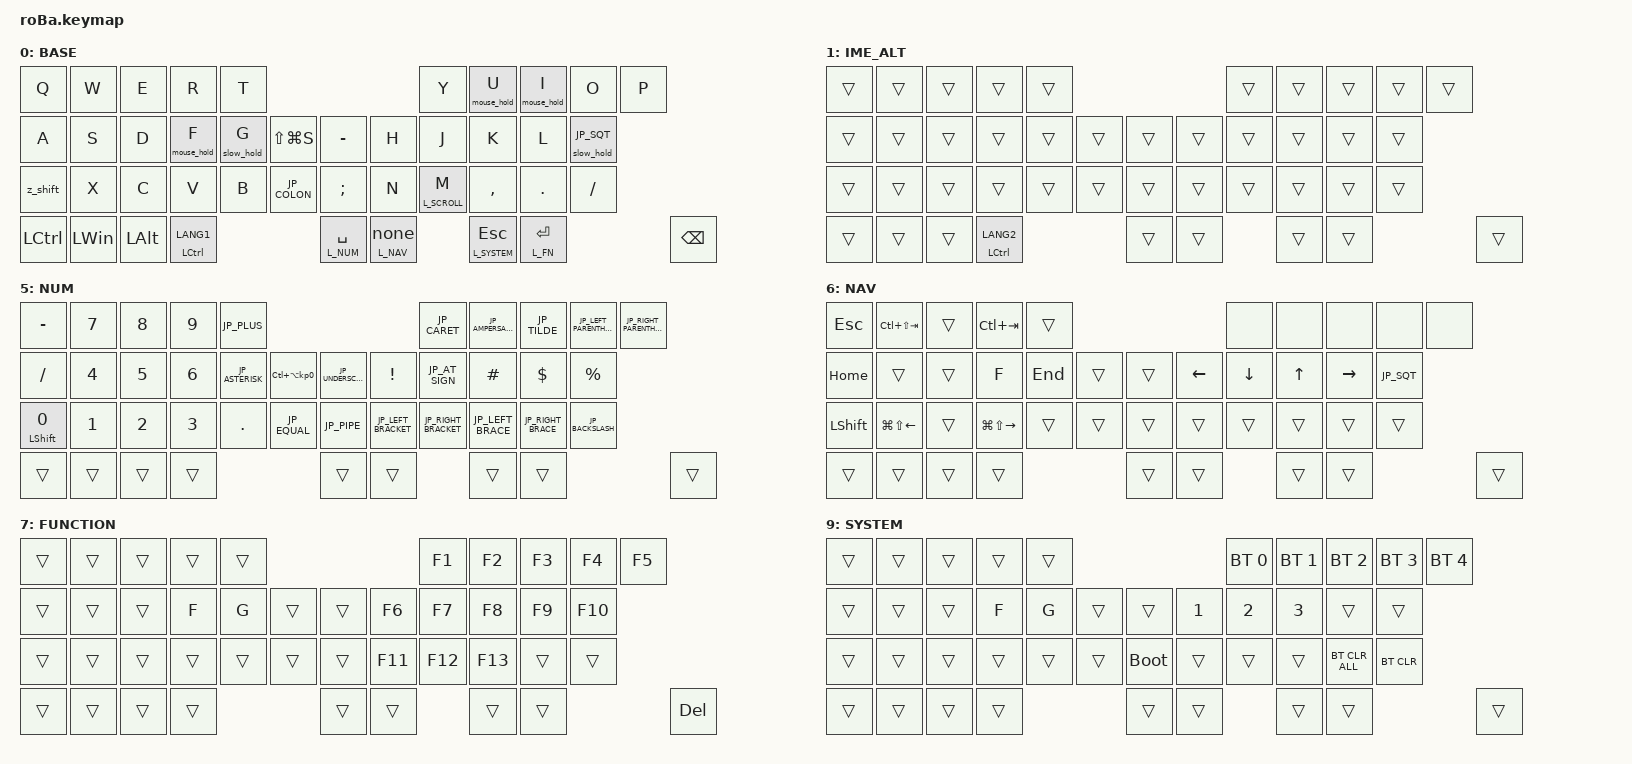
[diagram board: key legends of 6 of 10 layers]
#include <behaviors.dtsi>
#include <input/processors.dtsi>
#include <dt-bindings/zmk/bt.h>
#include <dt-bindings/zmk/keys.h>
#include <dt-bindings/zmk/modifiers.h>
#include <dt-bindings/zmk/pointing.h>

// JIS host layout: keep symbol positions, translate only the HID usage/modifier.
// Shift uses native JIS pairs, e.g. JP_AT_SIGN (@) -> ` and SEMICOLON -> +.
#define JP_SQT                  LS(NUMBER_7)
#define JP_DOUBLE_QUOTES        LS(NUMBER_2)
#define JP_COLON                SQT
#define JP_EQUAL                LS(MINUS)
#define JP_PLUS                 LS(SEMICOLON)
#define JP_ASTERISK             LS(SQT)
#define JP_CARET                EQUAL
#define JP_AMPERSAND            LS(NUMBER_6)
#define JP_TILDE                LS(EQUAL)
#define JP_AT_SIGN              LEFT_BRACKET
#define JP_LEFT_PARENTHESIS     LS(NUMBER_8)
#define JP_RIGHT_PARENTHESIS    LS(NUMBER_9)
#define JP_LEFT_BRACKET         RIGHT_BRACKET
#define JP_RIGHT_BRACKET        NON_US_HASH
#define JP_LEFT_BRACE           LS(RIGHT_BRACKET)
#define JP_RIGHT_BRACE          LS(NON_US_HASH)
#define JP_UNDERSCORE           LS(INT_RO)
#define JP_BACKSLASH            INT_RO
#define JP_PIPE                 LS(INT_YEN)

// Keep these numbers in the same order as the layer nodes below.
// Manual layers override automouse; SCROLL must be the highest pointing layer.
#define L_BASE    0
#define L_IME_ALT 1
#define L_MOUSE   2
#define L_MOUSE_HOLD 3
#define L_SLOW    4
#define L_NUM     5
#define L_NAV     6
#define L_FN      7
#define L_SCROLL  8
#define L_SYSTEM  9

// All pointing layers share controls; manual holds outlive automatic MOUSE.
// F/U/I/J+K share MOUSE_HOLD; G/right 21 share SLOW; M scrolls.
// Pointer holds require 200ms; overlapping letters must not trigger mouse entry.
// No positional early-hold rule: all overlaps stay undecided until release/timeout.
// Ctrl/NUM/Fn/NAV retain chords; Shift and pointer entries wait for their hold time.
// BASE I holds MOUSE_HOLD, but a new I press in a pointing layer is MB1.
// The entry press is not a click; hand off to F/U before re-pressing I.
// Existing combos keep priority. SYSTEM remains timer-only; IME hold is Ctrl.
#define AUTOMOUSE_PROCESSOR &mouse_dwell L_MOUSE 500
#define POINTING_BINDINGS \
    &trans  &trans  &trans  &trans  &trans  &kp LC(C)  &mouse_hold  &mkp MB1  &mkp MB2  &kp LC(V) \
    &trans  &trans  &trans  &mouse_hold  &slow_hold  &trans  &trans  &trans  &none  &none  &trans  &slow_hold \
    &trans  &trans  &trans  &trans  &trans  &trans  &trans  &trans  &mo L_SCROLL  &trans  &trans  &trans \
    &trans  &trans  &trans  &trans  &trans  &trans  &trans  &trans  &trans

// NUM 0/Shift waits for 200ms; rolling digits must not enable Shift.
&mt {
    flavor = "tap-preferred";
    tapping-term-ms = <200>;
    quick-tap-ms = <0>;
};

&trackball {
    // Disable the driver timer: motion_dwell is the sole automatic owner.
    automouse-layer = <0>;
    scroll-layers = <L_SCROLL>;
};

// This listener is enabled only on the pointing (right) half by its overlay.
// Apply both scalers whenever SLOW is active, including beneath SCROLL.
&trackball_listener {
    input-processors = <AUTOMOUSE_PROCESSOR>;
    slow {
        layers = <L_SLOW>;
        // Gate before scaling, so tiny raw motion still counts as activity.
        input-processors = <AUTOMOUSE_PROCESSOR>, <&zip_xy_scaler 1 4>, <&zip_scroll_scaler 1 4>;
    };
};

/ {
    mouse_dwell: mouse_dwell {
        compatible = "zmk,input-processor-motion-dwell";
        #input-processor-cells = <2>;
        manual-layer = <L_MOUSE_HOLD>;
        activity-layers = <L_MOUSE L_MOUSE_HOLD L_SLOW L_SCROLL>;
        activity-positions = <5 6 7 8 9 13 14 18 19 21 30>;
        dwell-ms = <200>;
        // Entry requires BOTH dwell and summed abs(X/Y), before SLOW scaling.
        // Initial tuning value in input counts, not screen pixels or millimetres.
        min-distance = <32>;
        max-gap-ms = <80>;
        require-prior-idle-ms = <300>;
        // Z and IME/Ctrl decide first; their typing/tap branches explicitly exit AUTO.
        excluded-positions = <5 6 7 8 9 13 14 18 19 21 22 30 34 35 36 37>;
    };

    combos {
        compatible = "zmk,combos";

        // Same keys, disjoint domains: BASE entry versus pointing middle click.
        mouse_entry {
            timeout-ms = <50>;
            key-positions = <18 19>;
            layers = <L_BASE L_IME_ALT>;
            bindings = <&mouse_hold>;
            slow-release;
        };

        middle_click {
            timeout-ms = <50>;
            key-positions = <18 19>;
            layers = <L_MOUSE L_MOUSE_HOLD L_SLOW L_SCROLL>;
            bindings = <&mkp MB3>;
        };

        tab {
            bindings = <&kp TAB>;
            key-positions = <11 12>;
            layers = <L_BASE L_IME_ALT L_MOUSE L_MOUSE_HOLD L_SLOW>;
        };

        shift_tab {
            bindings = <&kp LS(TAB)>;
            key-positions = <12 13>;
            layers = <L_BASE L_IME_ALT L_MOUSE L_MOUSE_HOLD L_SLOW>;
        };

        exit_mouse {
            bindings = <&mouse_off L_MOUSE>;
            key-positions = <11 10>;
            layers = <L_BASE L_IME_ALT L_MOUSE L_MOUSE_HOLD L_SLOW>;
        };

        double_quotation {
            bindings = <&kp JP_DOUBLE_QUOTES>;
            key-positions = <20 21>;
            // Position 21 is SLOW during pointing; do not capture that hold.
            layers = <L_BASE L_IME_ALT>;
        };

        eq {
            bindings = <&kp JP_EQUAL>;
            key-positions = <24 25>;
            layers = <L_BASE L_IME_ALT L_MOUSE L_MOUSE_HOLD L_SLOW>;
        };
    };

    behaviors {
        // NUM/Fn accept chords, while the standard &lt remains timer-only for SYSTEM.
        layer_chord: layer_chord {
            compatible = "zmk,behavior-hold-tap";
            #binding-cells = <2>;
            flavor = "hold-preferred";
            tapping-term-ms = <200>;
            quick-tap-ms = <0>;
            bindings = <&mo>, <&kp>;
        };

        // Tap calls the existing LANG macro; holding never changes its send-order bit.
        ime_ctrl: ime_ctrl {
            compatible = "zmk,behavior-hold-tap";
            #binding-cells = <2>;
            flavor = "hold-preferred";
            tapping-term-ms = <200>;
            quick-tap-ms = <0>;
            bindings = <&kp>, <&ime_toggle>;
        };

        scroll_tap: scroll_tap {
            compatible = "zmk,behavior-hold-tap";
            #binding-cells = <2>;
            flavor = "tap-preferred";
            tapping-term-ms = <200>;
            quick-tap-ms = <0>;
            bindings = <&mo>, <&kp>;
        };

        // NAV keeps its 200ms single hold and also resolves on another key press.
        nav_hold: nav_hold {
            compatible = "zmk,behavior-hold-tap";
            #binding-cells = <2>;
            flavor = "hold-preferred";
            tapping-term-ms = <200>;
            quick-tap-ms = <0>;
            bindings = <&mo>, <&none>;
        };

        // F, U, I and J+K share one owner, so handoffs retain the remaining holds.
        mouse_hold: mouse_hold {
            compatible = "zmk,behavior-mouse-hold";
            #binding-cells = <0>;
            layer = <L_MOUSE_HOLD>;
        };

        // G and right 21 share SLOW, independently of MOUSE_HOLD.
        slow_hold: slow_hold {
            compatible = "zmk,behavior-mouse-hold";
            #binding-cells = <0>;
            layer = <L_SLOW>;
        };

        slow_tap: slow_tap {
            compatible = "zmk,behavior-hold-tap";
            #binding-cells = <2>;
            flavor = "tap-preferred";
            tapping-term-ms = <200>;
            quick-tap-ms = <0>;
            bindings = <&slow_hold>, <&kp>;
        };

        // Reuse the existing U behavior for F/I, keeping U's saved binding name.
        u_mouse: u_mouse {
            compatible = "zmk,behavior-hold-tap";
            #binding-cells = <2>;
            flavor = "tap-preferred";
            tapping-term-ms = <200>;
            quick-tap-ms = <0>;
            bindings = <&mouse_hold>, <&kp>;
        };

        // Forward Shift synchronously and preserve the release-based sticky grace.
        shift_hold: shift_hold {
            compatible = "zmk,behavior-shift-hold";
            #binding-cells = <0>;
            bindings = <&z_sticky LEFT_SHIFT>;
        };

        // An unused Shift hold waits for one key for 200ms after release.
        z_sticky: z_sticky {
            compatible = "zmk,behavior-sticky-key";
            #binding-cells = <1>;
            bindings = <&kp>;
            release-after-ms = <200>;
            quick-release;
            ignore-modifiers;
        };

        // Z waits for 250ms even when another key is pressed or released.
        z_hold: z_hold {
            compatible = "zmk,behavior-hold-tap";
            #binding-cells = <2>;
            flavor = "tap-preferred";
            tapping-term-ms = <250>;
            quick-tap-ms = <0>;
            bindings = <&shift_hold>, <&z_tap>;
        };

        // A re-press while Shift is pending must not wait through another hold-tap.
        z_shift: z_shift {
            compatible = "zmk,behavior-mod-morph";
            #binding-cells = <0>;
            bindings = <&z_hold 0 0>, <&z_tap>;
            mods = <(MOD_LSFT | MOD_RSFT)>;
            keep-mods = <(MOD_LSFT | MOD_RSFT)>;
        };

        mouse_off: mouse_off {
            compatible = "zmk,behavior-toggle-layer";
            #binding-cells = <1>;
            toggle-mode = "off";
        };
    };

    macros {
        // Exit only on typing, not on the undecided Z press or its Shift hold.
        // Forward press/release rather than inserting a fixed-duration Z tap.
        z_tap: z_tap {
            compatible = "zmk,behavior-macro";
            #binding-cells = <0>;
            wait-ms = <0>;
            bindings = <&macro_press &mouse_off L_MOUSE &kp Z
                        &macro_pause_for_release &macro_release &kp Z>;
        };

        // Flip only the local send-order bit, not the host IME state.
        ime_toggle: ime_toggle {
            compatible = "zmk,behavior-macro-one-param";
            #binding-cells = <1>;
            wait-ms = <0>;
            bindings = <&macro_press &mouse_off L_MOUSE &tog L_IME_ALT
                        &macro_tap &macro_param_1to1 &kp MACRO_PLACEHOLDER>;
        };
    };

    keymap {
        compatible = "zmk,keymap";

        BASE {
            // Left thumb: IME/Ctrl, Space/NUM, hold-only NAV. Z holds Shift.
            // Right thumb: Esc/SYSTEM and Enter/FUNCTION; bottom-right: dedicated Backspace.
            bindings = <
&kp Q             &kp W         &kp E         &kp R                   &kp T                                               &kp Y        &u_mouse 0 U  &u_mouse 0 I  &kp O    &kp P
&kp A             &kp S         &kp D         &u_mouse 0 F                   &slow_tap 0 G        &kp LS(LG(S))    &kp MINUS  &kp H        &kp J  &kp K      &kp L    &slow_tap 0 JP_SQT
&z_shift         &kp X         &kp C         &kp V                   &kp B        &kp JP_COLON        &kp SEMICOLON       &kp N        &scroll_tap L_SCROLL M  &kp COMMA  &kp DOT  &kp SLASH
&kp LCTRL         &kp LEFT_WIN  &kp LEFT_ALT  &ime_ctrl LEFT_CONTROL LANG1  &layer_chord L_NUM SPACE  &nav_hold L_NAV 0  &lt L_SYSTEM ESCAPE  &layer_chord L_FN ENTER                     &kp BACKSPACE
            >;

            sensor-bindings = <&inc_dec_kp PG_UP PAGE_DOWN>;
        };

        // One send-order bit: off -> LANG1, on -> LANG2. Starts off at boot.
        // All other keys/sensors inherit; keep this below every operation layer.
        IME_ALT {
            bindings = <
&trans  &trans  &trans  &trans  &trans                              &trans  &trans  &trans  &trans  &trans
&trans  &trans  &trans  &trans  &trans  &trans      &trans  &trans  &trans  &trans  &trans  &trans
&trans  &trans  &trans  &trans  &trans  &trans      &trans  &trans  &trans  &trans  &trans  &trans
&trans  &trans  &trans  &ime_ctrl LEFT_CONTROL LANG2  &trans  &trans      &trans  &trans                  &trans
            >;
        };

        MOUSE {
            bindings = <POINTING_BINDINGS>;
        };

        // Independent of the automatic timeout; released after the last F/U/I/J+K hold.
        MOUSE_HOLD {
            bindings = <POINTING_BINDINGS>;
        };

        // Below manual layers: cannot turn a held SCROLL into pointer motion.
        SLOW {
            bindings = <POINTING_BINDINGS>;
        };

        NUM {
            // Number-row usages and JP_* symbols expect a JIS host layout.
            bindings = <
&kp MINUS                   &kp NUMBER_7     &kp NUMBER_8     &kp NUMBER_9     &kp JP_PLUS                                                     &kp JP_CARET         &kp JP_AMPERSAND      &kp JP_TILDE       &kp JP_LEFT_PARENTHESIS  &kp JP_RIGHT_PARENTHESIS
&kp SLASH                   &kp NUMBER_4     &kp NUMBER_5     &kp NUMBER_6     &kp JP_ASTERISK  &kp LC(LA(KP_NUMBER_0))    &kp JP_UNDERSCORE  &kp EXCLAMATION   &kp JP_AT_SIGN        &kp HASH        &kp DOLLAR            &kp PERCENT
&mt LEFT_SHIFT NUMBER_0      &kp NUMBER_1     &kp NUMBER_2     &kp NUMBER_3     &kp PERIOD    &kp JP_EQUAL                  &kp JP_PIPE        &kp JP_LEFT_BRACKET  &kp JP_RIGHT_BRACKET  &kp JP_LEFT_BRACE  &kp JP_RIGHT_BRACE       &kp JP_BACKSLASH
&trans                      &trans           &trans           &trans           &trans        &trans                     &trans          &trans                                                                     &trans
            >;
        };

        NAV {
            // Unused Y/U/I/O/P positions block both letters and lower-layer actions.
            bindings = <
&kp ESCAPE      &kp LC(LS(TAB))         &trans  &kp LC(TAB)              &trans                                  &none           &none           &none         &none            &none
&kp HOME        &trans                  &trans  &kp F                  &kp END  &trans      &trans  &kp LEFT_ARROW  &kp DOWN_ARROW  &kp UP_ARROW  &kp RIGHT_ARROW  &kp JP_SQT
&kp LEFT_SHIFT  &kp LG(LS(LEFT_ARROW))  &trans  &kp LG(LS(RIGHT_ARROW))  &trans   &trans      &trans        &trans          &trans          &trans        &trans           &trans
&trans          &trans                  &trans  &trans                  &trans   &trans      &trans        &trans                                                        &trans
            >;

            sensor-bindings = <&inc_dec_kp LC(PAGE_UP) LC(PAGE_DOWN)>;
        };

        FUNCTION {
            bindings = <
&trans  &trans  &trans  &trans  &trans                                  &kp F1   &kp F2   &kp F3   &kp F4  &kp F5
&trans  &trans  &trans  &kp F  &kp G  &trans      &trans  &kp F6   &kp F7   &kp F8   &kp F9  &kp F10
&trans  &trans  &trans  &trans  &trans  &trans      &trans        &kp F11  &kp F12  &kp F13  &trans  &trans
&trans  &trans  &trans  &trans  &trans  &trans      &trans        &trans                               &kp DEL
            >;
        };

        SCROLL {
            bindings = <POINTING_BINDINGS>;
        };

        SYSTEM {
            bindings = <
&trans  &trans        &trans        &trans        &trans                             &bt BT_SEL 0  &bt BT_SEL 1  &bt BT_SEL 2  &bt BT_SEL 3    &bt BT_SEL 4
&trans  &trans        &trans        &kp F        &kp G  &trans      &trans     &kp NUMBER_1        &kp NUMBER_2        &kp NUMBER_3        &trans          &trans
&trans  &trans  &trans  &trans  &trans  &trans      &bootloader   &trans        &trans        &trans        &bt BT_CLR_ALL  &bt BT_CLR
&trans  &trans        &trans        &trans        &trans  &trans      &trans        &trans                                                        &trans
            >;
        };
    };
};
